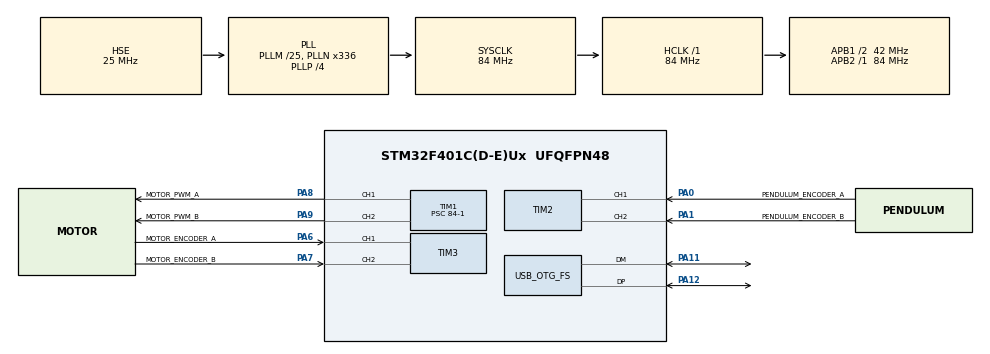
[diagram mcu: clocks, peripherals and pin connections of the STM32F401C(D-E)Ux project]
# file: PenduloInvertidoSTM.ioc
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Mcu.Family=STM32F4
Mcu.Name=STM32F401C(D-E)Ux
Mcu.Package=UFQFPN48
NVIC.OTG_FS_IRQn=true\:0\:0\:false\:false\:true\:false\:true\:true
NVIC.PriorityGroup=NVIC_PRIORITYGROUP_4
NVIC.TIM2_IRQn=true\:0\:0\:false\:false\:true\:true\:true\:true
NVIC.TIM3_IRQn=true\:0\:0\:false\:false\:true\:true\:true\:true
PA0-WKUP.GPIO_Label=PENDULUM_ENCODER_A
PA0-WKUP.Signal=S_TIM2_CH1_ETR
PA1.GPIO_Label=PENDULUM_ENCODER_B
PA1.Signal=S_TIM2_CH2
PA11.Mode=Device_Only
PA11.Signal=USB_OTG_FS_DM
PA12.Mode=Device_Only
PA12.Signal=USB_OTG_FS_DP
PA13.Mode=Serial_Wire
PA13.Signal=SYS_JTMS-SWDIO
PA14.Mode=Serial_Wire
PA14.Signal=SYS_JTCK-SWCLK
PA6.GPIO_Label=MOTOR_ENCODER_A
PA6.Signal=S_TIM3_CH1
PA7.GPIO_Label=MOTOR_ENCODER_B
PA7.Signal=S_TIM3_CH2
PA8.GPIO_Label=MOTOR_PWM_A
PA8.Signal=S_TIM1_CH1
PA9.GPIO_Label=MOTOR_PWM_B
PA9.Signal=S_TIM1_CH2
PB6.Signal=USART1_TX
PB7.Signal=USART1_RX
PH0\ -\ OSC_IN.Mode=HSE-External-Oscillator
PH0\ -\ OSC_IN.Signal=RCC_OSC_IN
PH1\ -\ OSC_OUT.Mode=HSE-External-Oscillator
PH1\ -\ OSC_OUT.Signal=RCC_OSC_OUT
ProjectManager.HeapSize=0x600
ProjectManager.StackSize=0x400
ProjectManager.TargetToolchain=STM32CubeIDE
RCC.48MHZClocksFreq_Value=48000000
RCC.AHBFreq_Value=84000000
RCC.APB1CLKDivider=RCC_HCLK_DIV2
RCC.APB1Freq_Value=42000000
RCC.APB1TimFreq_Value=84000000
RCC.APB2Freq_Value=84000000
RCC.APB2TimFreq_Value=84000000
RCC.CortexFreq_Value=84000000
RCC.HCLKFreq_Value=84000000
RCC.HSE_VALUE=25000000
RCC.HSI_VALUE=16000000
RCC.LSE_VALUE=32768
RCC.PLLM=25
RCC.PLLN=336
RCC.PLLP=RCC_PLLP_DIV4
RCC.PLLQ=7
RCC.SYSCLKFreq_VALUE=84000000
RCC.SYSCLKSource=RCC_SYSCLKSOURCE_PLLCLK
RCC.VCOOutputFreq_Value=336000000
SH.S_TIM1_CH1.0=TIM1_CH1,PWM Generation1 CH1
SH.S_TIM1_CH2.0=TIM1_CH2,PWM Generation2 CH2
SH.S_TIM2_CH1_ETR.0=TIM2_CH1,Encoder_Interface
SH.S_TIM2_CH2.0=TIM2_CH2,Encoder_Interface
SH.S_TIM3_CH1.0=TIM3_CH1,Encoder_Interface
SH.S_TIM3_CH2.0=TIM3_CH2,Encoder_Interface
TIM1.Channel-PWM\ Generation1\ CH1=TIM_CHANNEL_1
TIM1.Channel-PWM\ Generation2\ CH2=TIM_CHANNEL_2
TIM1.Period=1000-1
TIM1.Prescaler=84-1
TIM2.EncoderMode=TIM_ENCODERMODE_TI12
TIM2.IC1Polarity=TIM_ICPOLARITY_FALLING
TIM2.IC2Polarity=TIM_ICPOLARITY_FALLING
TIM3.EncoderMode=TIM_ENCODERMODE_TI12
TIM3.IC1Polarity=TIM_ICPOLARITY_FALLING
TIM3.IC2Polarity=TIM_ICPOLARITY_FALLING
USB_DEVICE.CLASS_NAME_FS=CDC
USB_DEVICE.VirtualMode-CDC_FS=Cdc
USB_DEVICE.VirtualModeFS=Cdc_FS
USB_OTG_FS.VirtualMode=Device_Only
VP_TIM1_VS_ClockSourceINT.Mode=Internal
VP_USB_DEVICE_VS_USB_DEVICE_CDC_FS.Mode=CDC_FS
board=custom

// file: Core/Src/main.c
/* USER CODE BEGIN Header */
/**
  ******************************************************************************
  * @file           : main.c
  * @brief          : Main program body
  ******************************************************************************
  * @attention
  *
  * Copyright (c) 2023 STMicroelectronics.
  * All rights reserved.
  *
  * This software is licensed under terms that can be found in the LICENSE file
  * in the root directory of this software component.
  * If no LICENSE file comes with this software, it is provided AS-IS.
  *
  ******************************************************************************
  */
/* USER CODE END Header */
#include "main.h"
#include "usb_device.h"

/* USER CODE BEGIN Includes */
#include "../../app/app.h"

/* USER CODE END Includes */

TIM_HandleTypeDef htim1;
TIM_HandleTypeDef htim2;
TIM_HandleTypeDef htim3;

void SystemClock_Config(void);
static void MX_GPIO_Init(void);
static void MX_TIM2_Init(void);
static void MX_TIM3_Init(void);
static void MX_TIM1_Init(void);

int main(void)
{

  /* MCU Configuration--------------------------------------------------------*/

  /* Reset of all peripherals, Initializes the Flash interface and the Systick. */
  HAL_Init();

  /* Configure the system clock */
  SystemClock_Config();

  /* Initialize all configured peripherals */
  MX_GPIO_Init();
  MX_TIM2_Init();
  MX_TIM3_Init();
  MX_TIM1_Init();
  MX_USB_DEVICE_Init();
  /* USER CODE BEGIN 2 */

  app_setup();

  /* USER CODE END 2 */

  /* Infinite loop */
  /* USER CODE BEGIN WHILE */
  while (1)
  {
	  app_loop();
    /* USER CODE END WHILE */

  }
}

void SystemClock_Config(void)
{
  RCC_OscInitTypeDef RCC_OscInitStruct = {0};
  RCC_ClkInitTypeDef RCC_ClkInitStruct = {0};

  /** Configure the main internal regulator output voltage
  */
  __HAL_RCC_PWR_CLK_ENABLE();
  __HAL_PWR_VOLTAGESCALING_CONFIG(PWR_REGULATOR_VOLTAGE_SCALE2);

  /** Initializes the RCC Oscillators according to the specified parameters
  * in the RCC_OscInitTypeDef structure.
  */
  RCC_OscInitStruct.OscillatorType = RCC_OSCILLATORTYPE_HSE;
  RCC_OscInitStruct.HSEState = RCC_HSE_ON;
  RCC_OscInitStruct.PLL.PLLState = RCC_PLL_ON;
  RCC_OscInitStruct.PLL.PLLSource = RCC_PLLSOURCE_HSE;
  RCC_OscInitStruct.PLL.PLLM = 25;
  RCC_OscInitStruct.PLL.PLLN = 336;
  RCC_OscInitStruct.PLL.PLLP = RCC_PLLP_DIV4;
  RCC_OscInitStruct.PLL.PLLQ = 7;
  if (HAL_RCC_OscConfig(&RCC_OscInitStruct) != HAL_OK)
  {
    Error_Handler();
  }

  /** Initializes the CPU, AHB and APB buses clocks
  */
  RCC_ClkInitStruct.ClockType = RCC_CLOCKTYPE_HCLK|RCC_CLOCKTYPE_SYSCLK
                              |RCC_CLOCKTYPE_PCLK1|RCC_CLOCKTYPE_PCLK2;
  RCC_ClkInitStruct.SYSCLKSource = RCC_SYSCLKSOURCE_PLLCLK;
  RCC_ClkInitStruct.AHBCLKDivider = RCC_SYSCLK_DIV1;
  RCC_ClkInitStruct.APB1CLKDivider = RCC_HCLK_DIV2;
  RCC_ClkInitStruct.APB2CLKDivider = RCC_HCLK_DIV1;

  if (HAL_RCC_ClockConfig(&RCC_ClkInitStruct, FLASH_LATENCY_2) != HAL_OK)
  {
    Error_Handler();
  }
}

static void MX_TIM1_Init(void)
{

  TIM_ClockConfigTypeDef sClockSourceConfig = {0};
  TIM_MasterConfigTypeDef sMasterConfig = {0};
  TIM_OC_InitTypeDef sConfigOC = {0};
  TIM_BreakDeadTimeConfigTypeDef sBreakDeadTimeConfig = {0};

  htim1.Instance = TIM1;
  htim1.Init.Prescaler = 84-1;
  htim1.Init.CounterMode = TIM_COUNTERMODE_UP;
  htim1.Init.Period = 1000-1;
  htim1.Init.ClockDivision = TIM_CLOCKDIVISION_DIV1;
  htim1.Init.RepetitionCounter = 0;
  htim1.Init.AutoReloadPreload = TIM_AUTORELOAD_PRELOAD_DISABLE;
  if (HAL_TIM_Base_Init(&htim1) != HAL_OK)
  {
    Error_Handler();
  }
  sClockSourceConfig.ClockSource = TIM_CLOCKSOURCE_INTERNAL;
  if (HAL_TIM_ConfigClockSource(&htim1, &sClockSourceConfig) != HAL_OK)
  {
    Error_Handler();
  }
  if (HAL_TIM_PWM_Init(&htim1) != HAL_OK)
  {
    Error_Handler();
  }
  sMasterConfig.MasterOutputTrigger = TIM_TRGO_RESET;
  sMasterConfig.MasterSlaveMode = TIM_MASTERSLAVEMODE_DISABLE;
  if (HAL_TIMEx_MasterConfigSynchronization(&htim1, &sMasterConfig) != HAL_OK)
  {
    Error_Handler();
  }
  sConfigOC.OCMode = TIM_OCMODE_PWM1;
  sConfigOC.Pulse = 0;
  sConfigOC.OCPolarity = TIM_OCPOLARITY_HIGH;
  sConfigOC.OCNPolarity = TIM_OCNPOLARITY_HIGH;
  sConfigOC.OCFastMode = TIM_OCFAST_DISABLE;
  sConfigOC.OCIdleState = TIM_OCIDLESTATE_RESET;
  sConfigOC.OCNIdleState = TIM_OCNIDLESTATE_RESET;
  if (HAL_TIM_PWM_ConfigChannel(&htim1, &sConfigOC, TIM_CHANNEL_1) != HAL_OK)
  {
    Error_Handler();
  }
  if (HAL_TIM_PWM_ConfigChannel(&htim1, &sConfigOC, TIM_CHANNEL_2) != HAL_OK)
  {
    Error_Handler();
  }
  sBreakDeadTimeConfig.OffStateRunMode = TIM_OSSR_DISABLE;
  sBreakDeadTimeConfig.OffStateIDLEMode = TIM_OSSI_DISABLE;
  sBreakDeadTimeConfig.LockLevel = TIM_LOCKLEVEL_OFF;
  sBreakDeadTimeConfig.DeadTime = 0;
  sBreakDeadTimeConfig.BreakState = TIM_BREAK_DISABLE;
  sBreakDeadTimeConfig.BreakPolarity = TIM_BREAKPOLARITY_HIGH;
  sBreakDeadTimeConfig.AutomaticOutput = TIM_AUTOMATICOUTPUT_DISABLE;
  if (HAL_TIMEx_ConfigBreakDeadTime(&htim1, &sBreakDeadTimeConfig) != HAL_OK)
  {
    Error_Handler();
  }
  HAL_TIM_MspPostInit(&htim1);

}

static void MX_TIM2_Init(void)
{

  TIM_Encoder_InitTypeDef sConfig = {0};
  TIM_MasterConfigTypeDef sMasterConfig = {0};

  htim2.Instance = TIM2;
  htim2.Init.Prescaler = 0;
  htim2.Init.CounterMode = TIM_COUNTERMODE_UP;
  htim2.Init.Period = 4294967295;
  htim2.Init.ClockDivision = TIM_CLOCKDIVISION_DIV1;
  htim2.Init.AutoReloadPreload = TIM_AUTORELOAD_PRELOAD_DISABLE;
  sConfig.EncoderMode = TIM_ENCODERMODE_TI12;
  sConfig.IC1Polarity = TIM_ICPOLARITY_FALLING;
  sConfig.IC1Selection = TIM_ICSELECTION_DIRECTTI;
  sConfig.IC1Prescaler = TIM_ICPSC_DIV1;
  sConfig.IC1Filter = 0;
  sConfig.IC2Polarity = TIM_ICPOLARITY_FALLING;
  sConfig.IC2Selection = TIM_ICSELECTION_DIRECTTI;
  sConfig.IC2Prescaler = TIM_ICPSC_DIV1;
  sConfig.IC2Filter = 0;
  if (HAL_TIM_Encoder_Init(&htim2, &sConfig) != HAL_OK)
  {
    Error_Handler();
  }
  sMasterConfig.MasterOutputTrigger = TIM_TRGO_RESET;
  sMasterConfig.MasterSlaveMode = TIM_MASTERSLAVEMODE_DISABLE;
  if (HAL_TIMEx_MasterConfigSynchronization(&htim2, &sMasterConfig) != HAL_OK)
  {
    Error_Handler();
  }

}

static void MX_TIM3_Init(void)
{

  TIM_Encoder_InitTypeDef sConfig = {0};
  TIM_MasterConfigTypeDef sMasterConfig = {0};

  htim3.Instance = TIM3;
  htim3.Init.Prescaler = 0;
  htim3.Init.CounterMode = TIM_COUNTERMODE_UP;
  htim3.Init.Period = 65535;
  htim3.Init.ClockDivision = TIM_CLOCKDIVISION_DIV1;
  htim3.Init.AutoReloadPreload = TIM_AUTORELOAD_PRELOAD_DISABLE;
  sConfig.EncoderMode = TIM_ENCODERMODE_TI12;
  sConfig.IC1Polarity = TIM_ICPOLARITY_FALLING;
  sConfig.IC1Selection = TIM_ICSELECTION_DIRECTTI;
  sConfig.IC1Prescaler = TIM_ICPSC_DIV1;
  sConfig.IC1Filter = 0;
  sConfig.IC2Polarity = TIM_ICPOLARITY_FALLING;
  sConfig.IC2Selection = TIM_ICSELECTION_DIRECTTI;
  sConfig.IC2Prescaler = TIM_ICPSC_DIV1;
  sConfig.IC2Filter = 0;
  if (HAL_TIM_Encoder_Init(&htim3, &sConfig) != HAL_OK)
  {
    Error_Handler();
  }
  sMasterConfig.MasterOutputTrigger = TIM_TRGO_RESET;
  sMasterConfig.MasterSlaveMode = TIM_MASTERSLAVEMODE_DISABLE;
  if (HAL_TIMEx_MasterConfigSynchronization(&htim3, &sMasterConfig) != HAL_OK)
  {
    Error_Handler();
  }

}

static void MX_GPIO_Init(void)
{
  GPIO_InitTypeDef GPIO_InitStruct = {0};

  /* GPIO Ports Clock Enable */
  __HAL_RCC_GPIOH_CLK_ENABLE();
  __HAL_RCC_GPIOA_CLK_ENABLE();
  __HAL_RCC_GPIOB_CLK_ENABLE();

  /*Configure GPIO pins : PB6 PB7 */
  GPIO_InitStruct.Pin = GPIO_PIN_6|GPIO_PIN_7;
  GPIO_InitStruct.Mode = GPIO_MODE_AF_PP;
  GPIO_InitStruct.Pull = GPIO_NOPULL;
  GPIO_InitStruct.Speed = GPIO_SPEED_FREQ_VERY_HIGH;
  GPIO_InitStruct.Alternate = GPIO_AF7_USART1;
  HAL_GPIO_Init(GPIOB, &GPIO_InitStruct);

}

void Error_Handler(void)
{
  __disable_irq();
  while (1)
  {
  }
}
